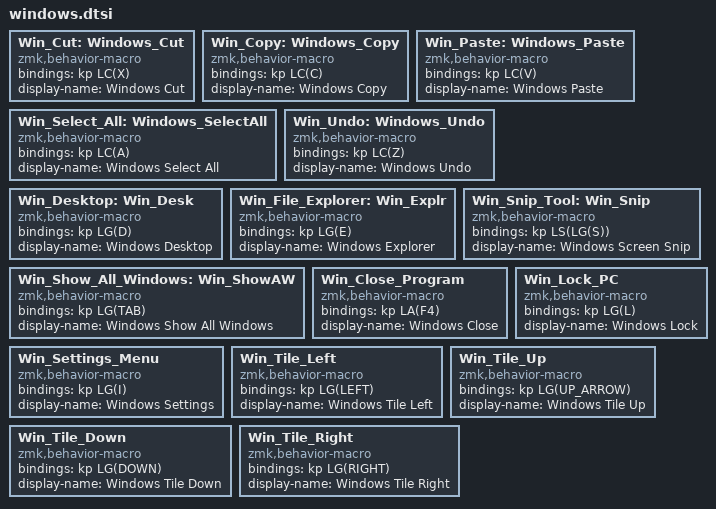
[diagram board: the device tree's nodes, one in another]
// ═══════════════════════════════════════════════════════════════
// Windows macros
// Version: 0.1
// Date: 05/Oct/2026
// ═══════════════════════════════════════════════════════════════

Win_Cut: Windows_Cut {
    compatible = "zmk,behavior-macro";
    #binding-cells = <0>;
    bindings = <&kp LC(X)>;
    display-name = "Windows Cut";
};

Win_Copy: Windows_Copy {
    compatible = "zmk,behavior-macro";
    #binding-cells = <0>;
    bindings = <&kp LC(C)>;
    display-name = "Windows Copy";
};

Win_Paste: Windows_Paste {
    compatible = "zmk,behavior-macro";
    #binding-cells = <0>;
    bindings = <&kp LC(V)>;
    display-name = "Windows Paste";
};

Win_Select_All: Windows_SelectAll {
    compatible = "zmk,behavior-macro";
    #binding-cells = <0>;
    bindings = <&kp LC(A)>;
    display-name = "Windows Select All";
};

Win_Undo: Windows_Undo {
    compatible = "zmk,behavior-macro";
    #binding-cells = <0>;
    bindings = <&kp LC(Z)>;
    display-name = "Windows Undo";
};

Win_Desktop: Win_Desk {
    compatible = "zmk,behavior-macro";
    #binding-cells = <0>;
    bindings = <&kp LG(D)>;
    display-name = "Windows Desktop";
};

Win_File_Explorer: Win_Explr {
    compatible = "zmk,behavior-macro";
    #binding-cells = <0>;
    bindings = <&kp LG(E)>;
    display-name = "Windows Explorer";
};

Win_Snip_Tool: Win_Snip {
    compatible = "zmk,behavior-macro";
    #binding-cells = <0>;
    bindings = <&kp LS(LG(S))>;
    display-name = "Windows Screen Snip";
};

Win_Show_All_Windows: Win_ShowAW {
    compatible = "zmk,behavior-macro";
    #binding-cells = <0>;
    bindings = <&kp LG(TAB)>;
    display-name = "Windows Show All Windows";
};

Win_Close_Program: Win_Close_Program {
    compatible = "zmk,behavior-macro";
    #binding-cells = <0>;
    bindings = <&kp LA(F4)>;
    display-name = "Windows Close";
};

Win_Settings_Menu: Win_Settings_Menu {
    compatible = "zmk,behavior-macro";
    #binding-cells = <0>;
    bindings = <&kp LG(I)>;
    display-name = "Windows Settings";
};

Win_Lock_PC: Win_Lock_PC {
    compatible = "zmk,behavior-macro";
    #binding-cells = <0>;
    bindings = <&kp LG(L)>;
    display-name = "Windows Lock";
};

Win_Tile_Left: Win_Tile_Left {
    compatible = "zmk,behavior-macro";
    #binding-cells = <0>;
    bindings = <&kp LG(LEFT)>;
    display-name = "Windows Tile Left";
};

Win_Tile_Up: Win_Tile_Up {
    compatible = "zmk,behavior-macro";
    #binding-cells = <0>;
    bindings = <&kp LG(UP_ARROW)>;
    display-name = "Windows Tile Up";
};

Win_Tile_Down: Win_Tile_Down {
    compatible = "zmk,behavior-macro";
    #binding-cells = <0>;
    bindings = <&kp LG(DOWN)>;
    display-name = "Windows Tile Down";
};

Win_Tile_Right: Win_Tile_Right {
    compatible = "zmk,behavior-macro";
    #binding-cells = <0>;
    bindings = <&kp LG(RIGHT)>;
    display-name = "Windows Tile Right";
};
